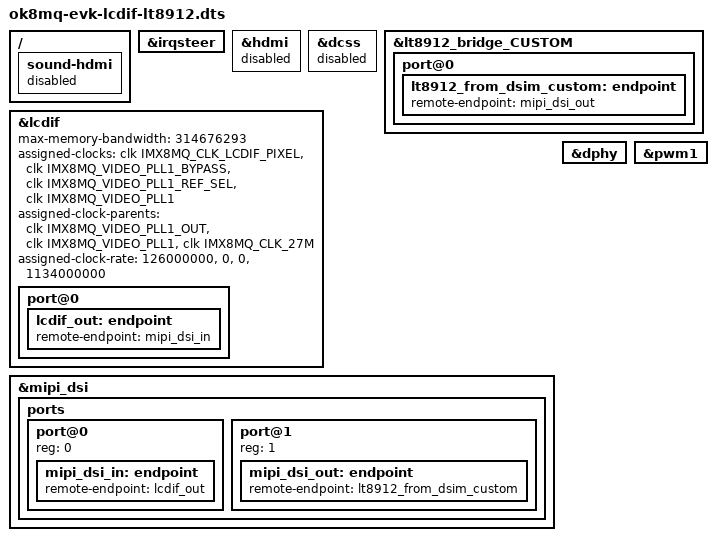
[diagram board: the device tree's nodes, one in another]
// SPDX-License-Identifier: GPL-2.0
/*
 * Copyright 2019 NXP.
 */

#include "ok8mq-evk.dts"

/ {
	sound-hdmi {
		status = "disabled";
	};
};

&irqsteer {
	status = "okay";
};

&hdmi {
	status = "disabled";
};

&dcss {
	status = "disabled";
};

&lt8912_bridge_CUSTOM {
	status = "okay";
	port@0 {
        
		lt8912_from_dsim_custom: endpoint {
			remote-endpoint = <&mipi_dsi_out>;
		};
	};
};

&lcdif {
	status = "okay";
	max-memory-bandwidth = <314676293>; /* 1280x1024-32@60 */

	assigned-clocks = <&clk IMX8MQ_CLK_LCDIF_PIXEL>,
			  <&clk IMX8MQ_VIDEO_PLL1_BYPASS>,
			  <&clk IMX8MQ_VIDEO_PLL1_REF_SEL>,
			  <&clk IMX8MQ_VIDEO_PLL1>;
	assigned-clock-parents = <&clk IMX8MQ_VIDEO_PLL1_OUT>,
				 <&clk IMX8MQ_VIDEO_PLL1>,
				 <&clk IMX8MQ_CLK_27M>;
	assigned-clock-rate = <126000000>, <0>, <0>, <1134000000>;

	port@0 {
		lcdif_out: endpoint {
			remote-endpoint = <&mipi_dsi_in>;
		};
	};
};


&mipi_dsi {
	status = "okay";
	ports {
		#address-cells = <1>;
		#size-cells = <0>;

		port@0 {
			reg = <0>;
			mipi_dsi_in: endpoint {
				remote-endpoint = <&lcdif_out>;
			};
		};

		port@1 {
			reg = <1>;
				mipi_dsi_out: endpoint {
				remote-endpoint = <&lt8912_from_dsim_custom>;
			};
		};
	};
};

&dphy {
        status = "okay";
};

&pwm1 {
	status = "okay";
};
